AUTOSAR XML (schema 00048)
package /AUTOLIV/SoftwareComponents/PRO
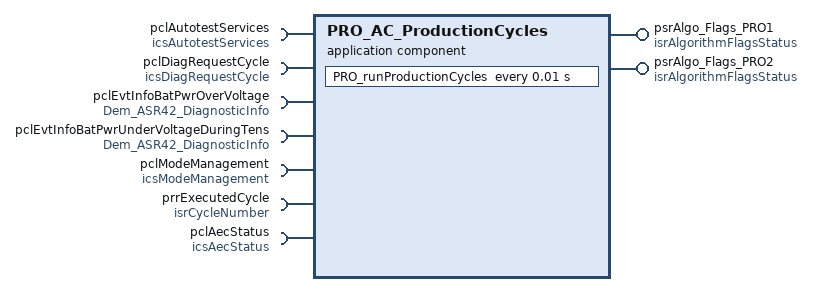
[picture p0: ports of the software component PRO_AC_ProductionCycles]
  application sw component type PRO_AC_ProductionCycles
    6 x require port:
      pclAutotestServices: required-com-specs=[GetLastCriticalAutotestID, GetTestResult], required-interface=icsAutotestServices
      pclDiagRequestCycle: required-com-specs=[ClearDiagRequestCycle, GetDiagRequestCycle], required-interface=icsDiagRequestCycle
      pclEvtInfoBatPwrOverVoltage: required-interface=Dem_ASR42_DiagnosticInfo
        required-com-specs:
          GetDTCOfEvent
          GetDebouncingOfEvent
          GetEventExtendedDataRecord
          GetEventExtendedDataRecordEx
          GetEventFailed
          GetEventFreezeFrameData
          GetEventFreezeFrameDataEx
          GetEventStatus
          GetEventTested
          GetFaultDetectionCounter
      pclEvtInfoBatPwrUnderVoltageDuringTens: required-interface=Dem_ASR42_DiagnosticInfo
        required-com-specs:
          GetDTCOfEvent
          GetDebouncingOfEvent
          GetEventExtendedDataRecord
          GetEventExtendedDataRecordEx
          GetEventFailed
          GetEventFreezeFrameData
          GetEventFreezeFrameDataEx
          GetEventStatus
          GetEventTested
          GetFaultDetectionCounter
      pclModeManagement: client-com-spec=CheckModeStatus, required-interface=icsModeManagement
      prrExecutedCycle: nonqueued-receiver-com-spec{data-element=u8CycleNumber, init-value=constant-reference=APPLINIT_KU8_CYCLE_NUMBER_NONE}, required-interface=isrCycleNumber
    provide port psrAlgo_Flags_PRO1: provided-interface=isrAlgorithmFlagsStatus
      provided-com-specs:
        data-element=b8InterruptFlag, uses-end-to-end-protection=true, init-value=constant-reference=APPLINIT_KB8_ALGO_FLAG_FALSE
        data-element=b8PreActivationFlag, uses-end-to-end-protection=true, init-value=constant-reference=APPLINIT_KB8_ALGO_FLAG_FALSE
        data-element=b8PreConditionsFlag, uses-end-to-end-protection=true, init-value=constant-reference=APPLINIT_KB8_ALGO_FLAG_FALSE
        data-element=b8TriggerFlag, uses-end-to-end-protection=true, init-value=constant-reference=APPLINIT_KB8_ALGO_FLAG_FALSE
        data-element=u8TriggeringSource, uses-end-to-end-protection=true, init-value=constant-reference=APPLINIT_KU8_TRIGGERING_SOURCE_NO
    provide port psrAlgo_Flags_PRO2: provided-interface=isrAlgorithmFlagsStatus
      provided-com-specs:
        data-element=b8InterruptFlag, uses-end-to-end-protection=true, init-value=constant-reference=APPLINIT_KB8_ALGO_FLAG_FALSE
        data-element=b8PreActivationFlag, uses-end-to-end-protection=true, init-value=constant-reference=APPLINIT_KB8_ALGO_FLAG_FALSE
        data-element=b8PreConditionsFlag, uses-end-to-end-protection=true, init-value=constant-reference=APPLINIT_KB8_ALGO_FLAG_FALSE
        data-element=b8TriggerFlag, uses-end-to-end-protection=true, init-value=constant-reference=APPLINIT_KB8_ALGO_FLAG_FALSE
        data-element=u8TriggeringSource, uses-end-to-end-protection=true, init-value=constant-reference=APPLINIT_KU8_TRIGGERING_SOURCE_NO
    require port pclAecStatus: required-interface=icsAecStatus
      required-com-specs:
        SetAecEvent
        GetNumberOfImplementedAec
        GetAecStatus
        GetAecQualificationCount
        GetAecNvpBlockRecordingStatus
        GetAecGroupsStatus
        GetAecDeskillThrs
    behavior PRO_IB_ProductionCycles: data-type-mapping=DataTypeMappingSet_PP4G
      timing event PRO_evProductionCycles: start-on-event=PRO_runProductionCycles, period=0.01
      runnable PRO_runProductionCycles
        data-receive-point-by-arguments:
          access DRP_prrExecutedCycle_u8CycleNumber: accessed-variable=prrExecutedCycle.u8CycleNumber
        data-send-points:
          10 x access:
            DSP_psrAlgo_Flags_PRO1_b8InterruptFlag: accessed-variable=psrAlgo_Flags_PRO1.b8InterruptFlag
            DSP_psrAlgo_Flags_PRO1_b8PreActivationFlag: accessed-variable=psrAlgo_Flags_PRO1.b8PreActivationFlag
            DSP_psrAlgo_Flags_PRO1_b8PreConditionsFlag: accessed-variable=psrAlgo_Flags_PRO1.b8PreConditionsFlag
            DSP_psrAlgo_Flags_PRO1_b8TriggerFlag: accessed-variable=psrAlgo_Flags_PRO1.b8TriggerFlag
            DSP_psrAlgo_Flags_PRO1_u8TriggeringSource: accessed-variable=psrAlgo_Flags_PRO1.u8TriggeringSource
            DSP_psrAlgo_Flags_PRO2_b8InterruptFlag: accessed-variable=psrAlgo_Flags_PRO2.b8InterruptFlag
            DSP_psrAlgo_Flags_PRO2_b8PreActivationFlag: accessed-variable=psrAlgo_Flags_PRO2.b8PreActivationFlag
            DSP_psrAlgo_Flags_PRO2_b8PreConditionsFlag: accessed-variable=psrAlgo_Flags_PRO2.b8PreConditionsFlag
            DSP_psrAlgo_Flags_PRO2_b8TriggerFlag: accessed-variable=psrAlgo_Flags_PRO2.b8TriggerFlag
            DSP_psrAlgo_Flags_PRO2_u8TriggeringSource: accessed-variable=psrAlgo_Flags_PRO2.u8TriggeringSource
        7 x sync call:
          SSCP_pclDiagRequestCycle_ClearDiagRequestCycle: operation=pclDiagRequestCycle.ClearDiagRequestCycle
          SSCP_pclDiagRequestCycle_GetDiagRequestCycle: operation=pclDiagRequestCycle.GetDiagRequestCycle
          SSCP_pclModeManagement_CheckModeStatus: operation=pclModeManagement.CheckModeStatus
          SSCP_pclTestResult_GetTestResult: operation=pclAutotestServices.GetTestResult
          scp_GetEventStatus: operation=pclEvtInfoBatPwrUnderVoltageDuringTens.GetEventStatus
          scp_GetEventStatus1: operation=pclEvtInfoBatPwrOverVoltage.GetEventStatus
          SC_pclAecStatus_GetAecStatus: operation=pclAecStatus.GetAecStatus
